# PY32F040Exx register map
Vendor: Puya; Series: PY32F0; File version: 1.0.0
CPU: CM0+ r0p1, little endian, no MPU, no FPU, 4 interrupt priority bits
Registers are 32-bit, read-write, reset 0x0 unless marked. A register's access mark holds for its fields unless they carry their own. Offsets are from the block's base; [hi:lo] are bit positions; {n}, {i} and the like mark numbered series.

## I2C1 — Inter integrated circuit
Base 0x40005400
Same registers: I2C2 0x40005800
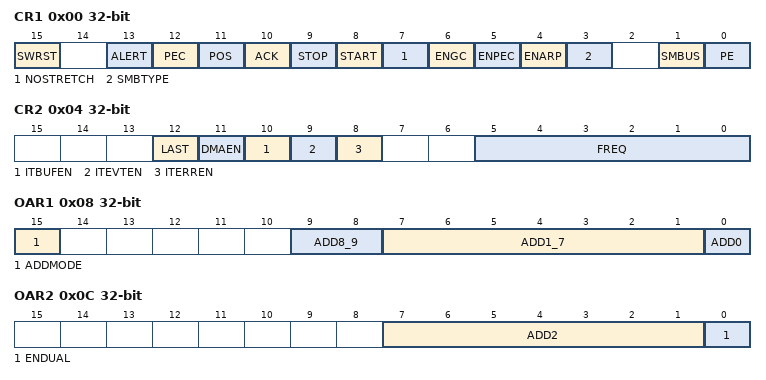
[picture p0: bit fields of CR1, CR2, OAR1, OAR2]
0x00 CR1
  [15] SWRST, [13] ALERT, [12] PEC, [11] POS, [10] ACK, [9] STOP, [8] START, [7] NOSTRETCH, [6] ENGC, [5] ENPEC, [4] ENARP, [3] SMBTYPE, [1] SMBUS, [0] PE
0x04 CR2
  [12] LAST, [11] DMAEN, [10] ITBUFEN, [9] ITEVTEN, [8] ITERREN, [5:0] FREQ
0x08 OAR1
  [15] ADDMODE, [9:8] ADD8_9, [7:1] ADD1_7, [0] ADD0
0x0C OAR2
  [7:1] ADD2, [0] ENDUAL
0x10 DR
  [7:0] DR
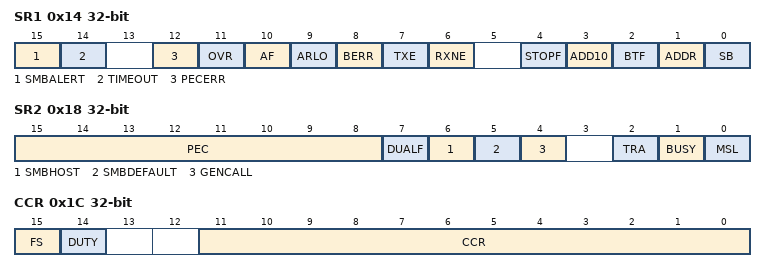
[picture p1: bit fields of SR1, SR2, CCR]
0x14 SR1
  [15] SMBALERT, [14] TIMEOUT, [12] PECERR, [11] OVR, [10] AF, [9] ARLO, [8] BERR, [7] TXE ro, [6] RXNE ro, [4] STOPF ro, [3] ADD10 ro, [2] BTF ro, [1] ADDR ro, [0] SB ro
0x18 SR2 ro
  [15:8] PEC, [7] DUALF, [6] SMBHOST, [5] SMBDEFAULT, [4] GENCALL, [2] TRA, [1] BUSY, [0] MSL
0x1C CCR
  [15] FS, [14] DUTY, [11:0] CCR
0x20 TRISE reset 0x2
  [5:0] TRISE

## IWDG — Independent watchdog
Base 0x40003000
0x00 KR wo — Key register (IWDG_KR)
  [15:0] KEY — Key value
0x04 PR — Prescaler register (IWDG_PR)
  [2:0] PR — Prescaler divider
0x08 RLR reset 0xFFF — Reload register (IWDG_RLR)
  [11:0] RL — Watchdog counter reload value
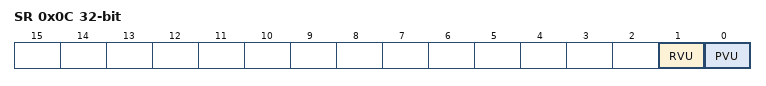
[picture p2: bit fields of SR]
0x0C SR ro — Status register (IWDG_SR)
  [1] RVU — Watchdog counter reload value update
  [0] PVU — Watchdog prescaler value update

## LCD — LCD CONTROLLER
Base 0x40002400
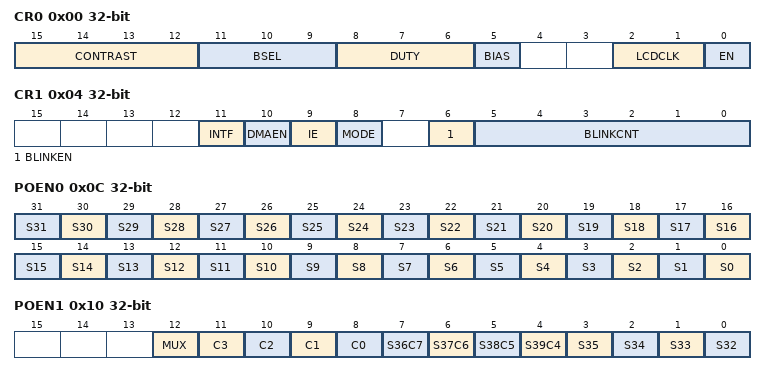
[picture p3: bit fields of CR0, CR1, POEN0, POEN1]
0x00 CR0 — Control register
  [15:12] CONTRAST, [11:9] BSEL, [8:6] DUTY, [5] BIAS, [2:1] LCDCLK, [0] EN
0x04 CR1
  [11] INTF, [10] DMAEN, [9] IE, [8] MODE, [6] BLINKEN, [5:0] BLINKCNT
0x08 INTCLR
  [10] INTF_CLR
0x0C POEN0
  [n] S{n} (n=0..31)
0x10 POEN1
  [12] MUX
  [n+8] C{n} (n=0..3)
  [7] S36C7 — S36
  [6] S37C6 — S37
  [5] S38C5 — S38
  [4] S39C4 — S39
  [n-32] S{n} (n=32..35)
{0x14+4i} RAM{i} (i=0..7) — des RAM{i}
  [31:0] D — des D
{0x14+4i} RAM{i} (i=8..15) — des RAM{i}
  [7:0] D — des D

## LPTIM1 — Low power timer
Base 0x40007C00
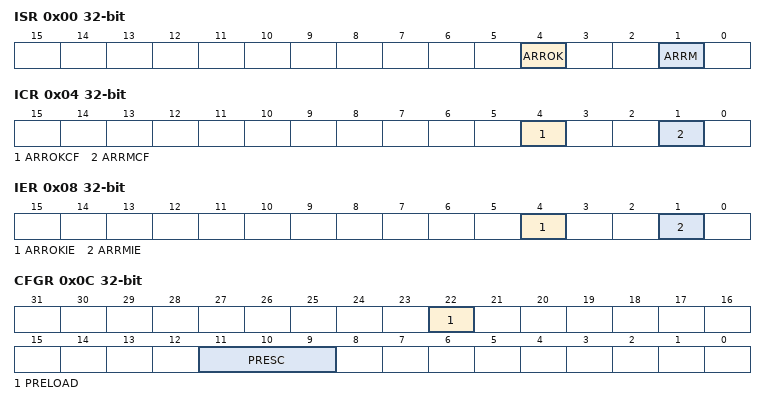
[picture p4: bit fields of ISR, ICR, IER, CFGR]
0x00 ISR ro — Interrupt and Status Register
  [4] ARROK — Autoreload match update OK
  [1] ARRM — Autoreload match
0x04 ICR wo — Interrupt Clear Register
  [4] ARROKCF — Autoreload match update OK Clear Flag
  [1] ARRMCF — Autoreload match Clear Flag
0x08 IER — Interrupt Enable Register
  [4] ARROKIE — Autoreload match update OK Interrupt Enable
  [1] ARRMIE — Autoreload matchInterrupt Enable
0x0C CFGR — Configuration Register
  [22] PRELOAD — Registers update mode
  [11:9] PRESC — Clock prescaler
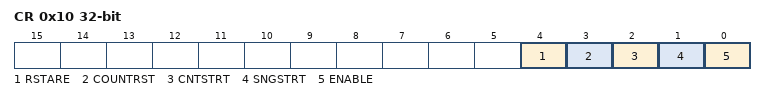
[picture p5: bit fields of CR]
0x10 CR — Control Register
  [4] RSTARE — Reset after read enable
  [3] COUNTRST — LPTIM counter reset
  [2] CNTSTRT
  [1] SNGSTRT — LPTIM start in single mode
  [0] ENABLE — LPTIM Enable
0x18 ARR reset 0x1 — Autoreload Register
  [15:0] ARR — Auto reload value
0x1C CNT ro — Counter Register
  [15:0] CNT — Counter value

## OPA — des OPA
Base 0x40010300
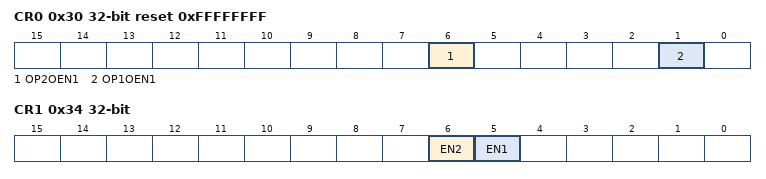
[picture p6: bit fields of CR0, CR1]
0x30 CR0 reset 0xFFFFFFFF
  [6] OP2OEN1, [1] OP1OEN1
0x34 CR1
  [6] EN2, [5] EN1

## PWR — Power control
Base 0x40007000
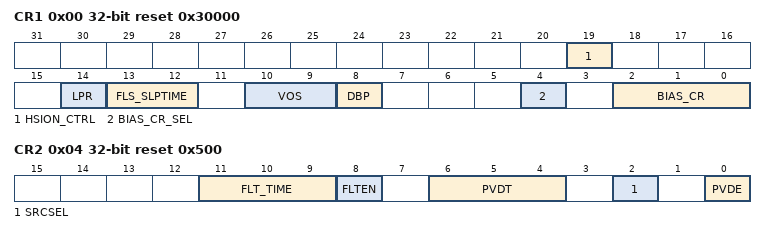
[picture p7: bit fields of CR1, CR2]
0x00 CR1 reset 0x30000 — Power control register 1
  [19] HSION_CTRL — HSI open time control
  [14] LPR — Low-power run
  [13:12] FLS_SLPTIME — Flash wait time after wakeup from the stop mode
  [10:9] VOS — Voltage scaling range selection
  [8] DBP — Disable backup domain write protection
  [4] BIAS_CR_SEL — MR Bias current selection
  [2:0] BIAS_CR — MR Bias current
0x04 CR2 reset 0x500 — Power control register 2
  [11:9] FLT_TIME — Digital filter time configuration
  [8] FLTEN — Digital filter enable
  [6:4] PVDT — Power voltage detector threshold selection
  [2] SRCSEL — Power voltage detector volatage selection
  [0] PVDE — Power voltage detector enable
0x14 SR ro — Power status register
  [11] PVDO — PVD output
